# I2C3 register map
Vendor: Texas Instruments
Peripheral module from a debugger description file (folder omap4430).
Registers are 16-bit, access per field, reset 0x0 unless marked. A register's access mark holds for its fields unless they carry their own. Offsets are as the file gives them; lines under a group give offsets from that group; [hi:lo] are bit positions; {n}, {i} and the like mark numbered series; 'fields as' and 'values as' point back to an identical list; <NAME> marks a mode.

## I2C3
0x00 I2C_REVNB_LO 32-bit ro reset not defined — IP Revision Identifier (X.Y.R) Used by software to track features, bugs, and compatibility
  [31:0] REVISION — IP Revision
0x04 I2C_REVNB_HI 32-bit ro reset not defined — IP Revision Identifier (X.Y.R) Used by software to track features, bugs, and compatibility
  [31:0] REVISION — IP Revision
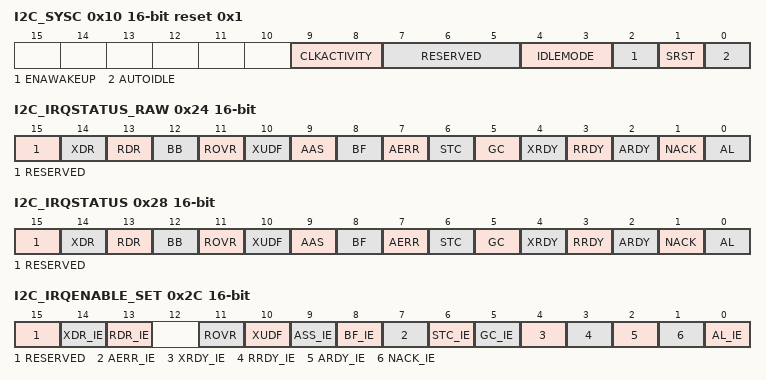
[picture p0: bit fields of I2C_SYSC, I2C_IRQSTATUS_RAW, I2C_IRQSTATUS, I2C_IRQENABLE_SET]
0x10 I2C_SYSC reset 0x1 — System Configuration register
  [9:8] CLKACTIVITY rw — Clock Activity selection bits
    0=Both clocks can be cut off; 1=Only OCP clock must be kept active; system clock can be cut off; 3=Both clocks must be kept active; 2=Only system clock must be kept active; OCP clock can be cut off
  [7:5] RESERVED ro — Reads return 0.
  [4:3] IDLEMODE rw — Idle Mode selection bits
    0=Force Idle mode; 1=No Idle mode; 3=smartidle_wakeup; 2=Smart Idle mode
  [2] ENAWAKEUP rw — Enable Wakeup control bit
    0=Wakeup mechanism is disabled; 1=Wakeup mechanism is enabled
  [1] SRST rw — SoftReset bit
    0=Normal mode; 1=The module is reset
  [0] AUTOIDLE rw — Autoidle bit
    0=Auto Idle mechanism is disabled; 1=Auto Idle mechanism is enabled
0x24 I2C_IRQSTATUS_RAW — Per-event raw interrupt status vector
  [15] RESERVED rw — Write 0s for future compatibility. Read returns 0.
  [14] XDR rw — Transmit draining IRQ status.
    0=Transmit draining inactive; 1=Transmit draining enabled
  [13] RDR rw — Receive draining IRQ status.
    0=Receive draining inactive; 1=Receive draining enabled
  [12] BB ro — Bus busy status.Writing into this bit has no effect.
    1=BB_1_r (Bus is occupied.); 0=BB_0_r (Bus is free.)
  [11] ROVR rw — Receive overrun status.Writing into this bit has no effect.
    1=ROVR_1_r (Receiver overrun.); 0=ROVR_0_r (Normal operation.)
  [10] XUDF rw — Transmit underflow status.Writing into this bit has no effect.
    1=XUDF_1_r (Transmit underflow.); 0=XUDF_0_r (Normal operation.)
  [9] AAS rw — Address recognized as slave IRQ status.
    0=No action; 1=Address recognized
  [8] BF rw — Bus Free IRQ status.
    0=No action; 1=Bus Free
  [7] AERR rw — Access Error IRQ status.
    0=No action; 1=Access Error
  [6] STC rw — Start Condition IRQ status.
    0=No action; 1=Start Condition detected
  [5] GC rw — General call IRQ status. Set to 1 by core when General call address detected and interrupt signaled to MPUSS.
    0=No general call detected; 1=General call address detected
  [4] XRDY rw — Transmit data ready IRQ status. Set to 1 by core when transmitter and when new data is requested. When set to 1 by core, an interrupt is signaled to MPUSS.
    0=Transmision ongoing; 1=Transmit data ready
  [3] RRDY rw — Receive data ready IRQ status. Set to 1 by core when receiver mode, a new data is able to be read. When set to 1 by core, an interrupt is signaled to MPUSS.
    0=No data available; 1=Receive data available
  [2] ARDY rw — Register access ready IRQ status. When set to 1 it indicates that previous access has been performed and registers are ready to be accessed again. An interrupt is signaled to MPUSS.
    0=Module busy; 1=Access ready
  [1] NACK rw — No acknowledgement IRQ status. Bit is set when No Acknowledge has been received, an interrupt is signaled to MPUSS.
    0=Normal operation; 1=Not Acknowledge detected
  [0] AL rw — Arbitration lost IRQ status. This bit is automatically set by the hardware when it loses the Arbitration in master transmit mode, an interrupt is signaled to MPUSS. During reads, it always returns 0.
    0=Normal operation; 1=Arbitration lost detected
0x28 I2C_IRQSTATUS access not given — Per-event enabled interrupt status vector
  [15] RESERVED rw — Write 0s for future compatibility. Read returns 0.
  [14] XDR — Transmit draining IRQ enabled status. (access RW W1toClr)
    0=Transmit draining inactive; 1=Transmit draining enabled
  [13] RDR — Receive draining IRQ enabled status. (access RW W1toClr)
    0=Receive draining inactive; 1=Receive draining enabled
  [12] BB ro — Bus busy enabled status.Writing into this bit has no effect.
    1=BB_1_r (Bus is occupied.); 0=BB_0_r (Bus is free.)
  [11] ROVR — Receive overrun enabled status.Writing into this bit has no effect. (access RW W1toClr)
    values as I2C_IRQSTATUS_RAW.ROVR
  [10] XUDF — Transmit underflow enabled status.Writing into this bit has no effect. (access RW W1toClr)
    values as I2C_IRQSTATUS_RAW.XUDF
  [9] AAS — Address recognized as slave IRQ enabled status. (access RW W1toClr)
    0=No action; 1=Address recognized
  [8] BF — Bus Free IRQ enabled status. (access RW W1toClr)
    0=No action; 1=Bus Free
  [7] AERR — Access Error IRQ enabled status. (access RW W1toClr)
    0=No action; 1=Access Error
  [6] STC — Start Condition IRQ enabled status. (access RW W1toClr)
    0=No action; 1=Start Condition detected
  [5] GC — General call IRQ enabled status. Set to 1 by core when General call address detected and interrupt signaled to MPUSS. Write 1 to clear. (access RW W1toClr)
    0=No general call detected; 1=General call address detected
  [4] XRDY — Transmit data ready IRQ enabled status. Set to 1 by core when transmitter and when new data is requested. When set to 1 by core, an interrupt is signaled to MPUSS. Write 1 to clear. (access RW W1toClr)
    0=Transmision ongoing; 1=Transmit data ready
  [3] RRDY — Receive data ready IRQ enabled status. Set to 1 by core when receiver mode, a new data is able to be read. When set to 1 by core, an interrupt is signaled to MPUSS. Write 1 to clear. (access RW W1toClr)
    0=No data available; 1=Receive data available
  [2] ARDY — Register access ready IRQ enabled status. When set to 1 it indicates that previous access has been performed and registers are ready to be accessed again. An interrupt is signaled to MPUSS. Write 1 to clear. (access RW W1toClr)
    0=Module busy; 1=Access ready
  [1] NACK — No acknowledgement IRQ enabled status. Bit is set when No Acknowledge has been received, an interrupt is signaled to MPUSS. Write 1 to clear this bit. (access RW W1toClr)
    0=Normal operation; 1=Not Acknowledge detected
  [0] AL — Arbitration lost IRQ enabled status. This bit is automatically set by the hardware when it loses the Arbitration in master transmit mode, an interrupt is signaled to MPUSS. During reads, it always returns 0. (access RW W1toClr)
    0=Normal operation; 1=Arbitration lost detected
0x2C I2C_IRQENABLE_SET — Per-event interrupt enable bit vector.
  [15] RESERVED rw — Write 0s for future compatibility. Read returns 0.
  [14] XDR_IE rw — Transmit Draining interrupt enable set. Mask or unmask the interrupt signaled by bit inI2C_STAT[XDR].
    0=Transmit Draining interrupt disabled; 1=Transmit Draining interrupt enabled
  [13] RDR_IE rw — Receive Draining interrupt enable set. Mask or unmask the interrupt signaled by bit inI2C_STAT[RDR].
    0=Receive Draining interrupt disabled; 1=Receive Draining interrupt enabled
  [11] ROVR rw — Receive overrun enable set.
    0=Receive overrun interrupt disabled; 1=Receive Draining interrupt enabled
  [10] XUDF rw — Transmit underflow enable set.
    0=Transmit underflow interrupt disabled; 1=Transmit underflow interrupt enabled
  [9] ASS_IE rw — Addressed as Slave interrupt enable set. Mask or unmask the interrupt signaled by bit inI2C_STAT[AAS].
    0=Addressed as Slave interrupt disabled; 1=Addressed as Slave interrupt enabled
  [8] BF_IE rw — Bus Free interrupt enable set. Mask or unmask the interrupt signaled by bit inI2C_STAT[BF].
    0=Bus Free interrupt disabled; 1=Bus Free interrupt enabled
  [7] AERR_IE rw — Access Error interrupt enable set. Mask or unmask the interrupt signaled by bit inI2C_STAT[AERR].
    0=Access Error interrupt disabled; 1=Access Error interrupt enabled
  [6] STC_IE rw — Start Condition interrupt enable set. Mask or unmask the interrupt signaled by bit inI2C_STAT[STC].
    0=Start Condition interrupt disabled; 1=Start Condition interrupt enabled
  [5] GC_IE rw — General call Interrupt enable set. Mask or unmask the interrupt signaled by bit inI2C_STAT[GC]
    0=General call interrupt disabled; 1=General call interrupt enabled
  [4] XRDY_IE rw — Transmit data ready interrupt enable set. Mask or unmask the interrupt signaled by bit inI2C_STAT[XRDY]
    0=Transmit data ready interrupt disabled; 1=Transmit data ready interrupt enabled
  [3] RRDY_IE rw — Receive data ready interrupt enable set. Mask or unmask the interrupt signaled by bit inI2C_STAT[RRDY]
    0=Receive data ready interrupt disabled; 1=Receive data ready interrupt enabled
  [2] ARDY_IE rw — Register access ready interrupt enable set. Mask or unmask the interrupt signaled by bit inI2C_STAT[ARDY]
    0=Register access ready interrupt disabled; 1=Register access ready interrupt enabled
  [1] NACK_IE rw — No acknowledgement interrupt enable set. Mask or unmask the interrupt signaled by bit inI2C_STAT[NACK]
    0=Not Acknowledge interrupt disabled; 1=Not Acknowledge interrupt enabled
  [0] AL_IE rw — Arbitration lost interrupt enable set. Mask or unmask the interrupt signaled by bit inI2C_STAT[AL]
    0=Arbitration lost interrupt disabled; 1=Arbitration lost interrupt enabled
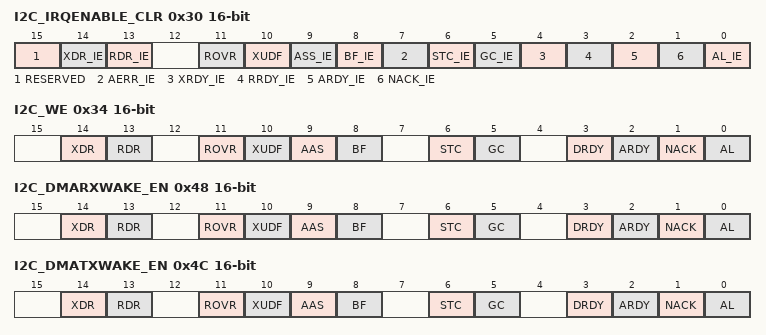
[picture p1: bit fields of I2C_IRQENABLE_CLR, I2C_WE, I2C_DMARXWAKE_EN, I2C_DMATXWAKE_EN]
0x30 I2C_IRQENABLE_CLR — Per-event interrupt clear bit vector.
  [15] RESERVED rw — Write 0s for future compatibility. Read returns 0.
  [14] XDR_IE rw — Transmit Draining interrupt enable clear. Mask or unmask the interrupt signaled by bit inI2C_STAT[XDR].
    values as I2C_IRQENABLE_SET.XDR_IE
  [13] RDR_IE rw — Receive Draining interrupt enable clear. Mask or unmask the interrupt signaled by bit inI2C_STAT[RDR].
    values as I2C_IRQENABLE_SET.RDR_IE
  [11] ROVR rw — Receive overrun enable clear.
    values as I2C_IRQENABLE_SET.ROVR
  [10] XUDF rw — Transmit underflow enable clear.
    values as I2C_IRQENABLE_SET.XUDF
  [9] ASS_IE rw — Addressed as Slave interrupt enable clear. Mask or unmask the interrupt signaled by bit inI2C_STAT[AAS].
    values as I2C_IRQENABLE_SET.ASS_IE
  [8] BF_IE rw — Bus Free interrupt enable clear. Mask or unmask the interrupt signaled by bit inI2C_STAT[BF].
    0=Bus Free interrupt disabled; 1=Bus Free interrupt enabled
  [7] AERR_IE rw — Access Error interrupt enable clear. Mask or unmask the interrupt signaled by bit inI2C_STAT[AERR].
    values as I2C_IRQENABLE_SET.AERR_IE
  [6] STC_IE rw — Start Condition interrupt enable clear. Mask or unmask the interrupt signaled by bit inI2C_STAT[STC].
    values as I2C_IRQENABLE_SET.STC_IE
  [5] GC_IE rw — General call Interrupt enable clear. Mask or unmask the interrupt signaled by bit inI2C_STAT[GC]
    values as I2C_IRQENABLE_SET.GC_IE
  [4] XRDY_IE rw — Transmit data ready interrupt enable clear. Mask or unmask the interrupt signaled by bit inI2C_STAT[XRDY]
    values as I2C_IRQENABLE_SET.XRDY_IE
  [3] RRDY_IE rw — Receive data ready interrupt enable clear. Mask or unmask the interrupt signaled by bit inI2C_STAT[RRDY]
    values as I2C_IRQENABLE_SET.RRDY_IE
  [2] ARDY_IE rw — Register access ready interrupt enable clear. Mask or unmask the interrupt signaled by bit inI2C_STAT[ARDY]
    values as I2C_IRQENABLE_SET.ARDY_IE
  [1] NACK_IE rw — No acknowledgement interrupt enable clear. Mask or unmask the interrupt signaled by bit inI2C_STAT[NACK]
    values as I2C_IRQENABLE_SET.NACK_IE
  [0] AL_IE rw — Arbitration lost interrupt enable clear. Mask or unmask the interrupt signaled by bit inI2C_STAT[AL]
    values as I2C_IRQENABLE_SET.AL_IE
0x34 I2C_WE — I2C wakeup enable vector.
  [14] XDR rw — Transmit Draining wakeup set.
    0=Transmit draining wakeup disabled; 1=Transmit draining wakeup enabled
  [13] RDR rw — Receive Draining wakeup set.
    0=Receive draining wakeup disabled; 1=Receive draining wakeup enabled
  [11] ROVR rw — Receive overrun wakeup set.
    0=Receive overrun wakeup disabled; 1=Receive overrun wakeup enabled
  [10] XUDF rw — Transmit underflow wakeup set.
    0=Transmit underflow wakeup disabled; 1=Transmit underflow wakeup enabled
  [9] AAS rw — Address as slave IRQ wakeup set.
    0=Addressed as slave wakeup disabled; 1=Addressed as slave wakeup enabled
  [8] BF rw — Bus Free IRQ wakeup set.
    0=Bus Free wakeup disabled; 1=Bus Free wakeup enabled
  [6] STC rw — Start Condition IRQ wakeup set.
    0=Start condition wakeup disabled; 1=Start condition wakeup enabled
  [5] GC rw — General call IRQ wakeup set.
    0=General call wakeup disabled; 1=General call wakeup enabled
  [3] DRDY rw — Receive/Transmit data ready IRQ wakeup set.
    0=Transmit/receive data ready wakeup disabled; 1=Transmit/receive data ready wakeup enabled
  [2] ARDY rw — Register access ready IRQ wakeup set.
    0=Register access ready wakeup disabled; 1=Register access ready wakeup enabled
  [1] NACK rw — No acknowledgment IRQ wakeup set.
    0=Not Acknowledge wakeup disabled; 1=Not Acknowledge wakeup enabled
  [0] AL rw — Arbitration lost IRQ wakeup set.
    0=Arbitration lost wakeup disabled; 1=Arbitration lost wakeup enabled
0x38 I2C_DMARXENABLE_SET — Per-event DMA RX enable set.
  [0] DMARX_ENABLE_SET rw — Receive DMA channel enable set.
0x3C I2C_DMATXENABLE_SET — Per-event DMA TX enable set.
  [0] DMATX_ENABLE_SET rw — Transmit DMA channel enable set.
0x40 I2C_DMARXENABLE_CLR — Per-event DMA RX enable clear.
  [0] DMARX_ENABLE_CLEAR rw — Receive DMA channel enable clear.
0x44 I2C_DMATXENABLE_CLR — Per-event DMA TX enable clear.
  [0] DMATX_ENABLE_CLEAR rw — Transmit DMA channel enable clear.
0x48 I2C_DMARXWAKE_EN — Per-event DMA RX wakeup enable.
  fields as I2C_WE
0x4C I2C_DMATXWAKE_EN — Per-event DMA TX wakeup enable.
  fields as I2C_WE
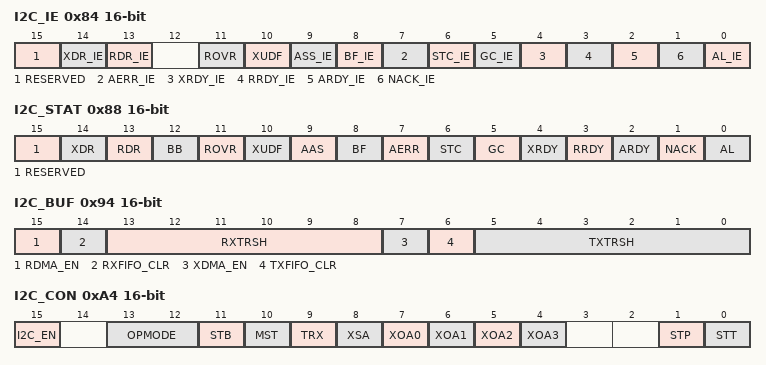
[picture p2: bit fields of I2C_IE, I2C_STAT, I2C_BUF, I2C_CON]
0x84 I2C_IE — I2C interrupt enable vector (legacy).
  [15] RESERVED rw — Write 0s for future compatibility. Read returns 0.
  [14] XDR_IE rw — Transmit Draining interrupt enable. Mask or unmask the interrupt signaled by bit inI2C_STAT[XDR].
    values as I2C_IRQENABLE_SET.XDR_IE
  [13] RDR_IE rw — Receive Draining interrupt enable. Mask or unmask the interrupt signaled by bit inI2C_STAT[RDR].
    values as I2C_IRQENABLE_SET.RDR_IE
  [11] ROVR rw — Receive overrun enable set.
    values as I2C_IRQENABLE_SET.ROVR
  [10] XUDF rw — Transmit underflow enable set.
    values as I2C_IRQENABLE_SET.XUDF
  [9] ASS_IE rw — Addressed as Slave interrupt enable. Mask or unmask the interrupt signaled by bit inI2C_STAT[AAS].
    values as I2C_IRQENABLE_SET.ASS_IE
  [8] BF_IE rw — Bus Free interrupt enable. Mask or unmask the interrupt signaled by bit inI2C_STAT[BF].
    0=Bus Free interrupt disabled; 1=Bus Free interrupt enabled
  [7] AERR_IE rw — Access Error interrupt enable. Mask or unmask the interrupt signaled by bit inI2C_STAT[AERR].
    values as I2C_IRQENABLE_SET.AERR_IE
  [6] STC_IE rw — Start Condition interrupt enable. Mask or unmask the interrupt signaled by bit inI2C_STAT[STC].
    values as I2C_IRQENABLE_SET.STC_IE
  [5] GC_IE rw — General call Interrupt enable. Mask or unmask the interrupt signaled by bit inI2C_STAT[GC]
    values as I2C_IRQENABLE_SET.GC_IE
  [4] XRDY_IE rw — Transmit data ready interrupt enable. Mask or unmask the interrupt signaled by bit inI2C_STAT[XRDY]
    values as I2C_IRQENABLE_SET.XRDY_IE
  [3] RRDY_IE rw — Receive data ready interrupt enable. Mask or unmask the interrupt signaled by bit inI2C_STAT[RRDY]
    values as I2C_IRQENABLE_SET.RRDY_IE
  [2] ARDY_IE rw — Register access ready interrupt enable. Mask or unmask the interrupt signaled by bit inI2C_STAT[ARDY]
    values as I2C_IRQENABLE_SET.ARDY_IE
  [1] NACK_IE rw — No acknowledgement interrupt enable. Mask or unmask the interrupt signaled by bit inI2C_STAT[NACK]
    values as I2C_IRQENABLE_SET.NACK_IE
  [0] AL_IE rw — Arbitration lost interrupt enable. Mask or unmask the interrupt signaled by bit inI2C_STAT[AL]
    values as I2C_IRQENABLE_SET.AL_IE
0x88 I2C_STAT access not given — I2C interrupt status vector (legacy).
  [15] RESERVED rw — Write 0s for future compatibility. Read returns 0.
  [14] XDR — Transmit draining IRQ status. (access RW W1toClr)
    0=Transmit draining inactive; 1=Transmit draining enabled
  [13] RDR — Receive draining IRQ status. (access RW W1toClr)
    0=Receive draining inactive; 1=Receive draining enabled
  [12] BB ro — Bus busy status.Writing into this bit has no effect.
    1=BB_1_r (Bus is occupied.); 0=BB_0_r (Bus is free.)
  [11] ROVR — Receive overrun status.Writing into this bit has no effect. (access RW W1toClr)
    values as I2C_IRQSTATUS_RAW.ROVR
  [10] XUDF — Transmit underflow status.Writing into this bit has no effect. (access RW W1toClr)
    values as I2C_IRQSTATUS_RAW.XUDF
  [9] AAS — Address recognized as slave IRQ status. (access RW W1toClr)
    0=No action; 1=Address recognized
  [8] BF — Bus Free IRQ status. (access RW W1toClr)
    0=No action; 1=Bus Free
  [7] AERR — Access Error IRQ status. (access RW W1toClr)
    0=No action; 1=Access Error
  [6] STC — Start Condition IRQ status. (access RW W1toClr)
    0=No action; 1=Start Condition detected
  [5] GC — General call IRQ status. Set to 1 by core when General call address detected and interrupt signaled to MPUSS. Write 1 to clear. (access RW W1toClr)
    0=No general call detected; 1=General call address detected
  [4] XRDY — Transmit data ready IRQ status. Set to 1 by core when transmitter and when new data is requested. When set to 1 by core, an interrupt is signaled to MPUSS. Write 1 to clear. (access RW W1toClr)
    0=Transmision ongoing; 1=Transmit data ready
  [3] RRDY — Receive data ready IRQ status. Set to 1 by core when receiver mode, a new data is able to be read. When set to 1 by core, an interrupt is signaled to MPUSS. Write 1 to clear. (access RW W1toClr)
    0=No data available; 1=Receive data available
  [2] ARDY — Register access ready IRQ status. When set to 1 it indicates that previous access has been performed and registers are ready to be accessed again. An interrupt is signaled to MPUSS. Write 1 to clear. (access RW W1toClr)
    0=Module busy; 1=Access ready
  [1] NACK — No acknowledgement IRQ status. Bit is set when No Acknowledge has been received, an interrupt is signaled to MPUSS. Write 1 to clear this bit. (access RW W1toClr)
    0=Normal operation; 1=Not Acknowledge detected
  [0] AL — Arbitration lost IRQ status. This bit is automatically set by the hardware when it loses the Arbitration in master transmit mode, an interrupt is signaled to MPUSS. During reads, it always returns 0. (access RW W1toClr)
    0=Normal operation; 1=Arbitration lost detected
0x90 I2C_SYSS reset 0x1 — System Status register
  [0] RDONE rw — Reset done bit
    1=RDONE_1_r (Reset completed); 0=RDONE_0_r (Internal module reset in ongoing)
0x94 I2C_BUF rw — Buffer Configuration register
  [15] RDMA_EN — Receive DMA channel enable
    0=Receive DMA channel disabled; 1=Receive DMA channel enabled
  [14] RXFIFO_CLR — Receive FIFO clear
    0=Normal mode; 1=Rx FIFO is reset
  [13:8] RXTRSH — Threshold value for FIFO buffer in RX mode
  [7] XDMA_EN — Transmit DMA channel enable
    0=Transmit DMA channel disabled; 1=Transmit DMA channel enabled
  [6] TXFIFO_CLR — Transmit FIFO clear
    0=Normal mode; 1=Tx FIFO is reset
  [5:0] TXTRSH — Threshold value for FIFO buffer in TX mode
0x98 I2C_CNT rw — Data counter register
  [15:0] DCOUNT — Data count Because the transfer length for DCOUNT = 0x0000 is 65536, the module does not allow the initiation of zero-data-byte transfers.
0x9C I2C_DATA (reset mask 0xFF00) — Data access register
  [7:0] DATA rw — Transmit/Receive data FIFO endpoint
0xA4 I2C_CON — I2C configuration register.
  [15] I2C_EN rw — I2C module enable.
    0=Controller in reset. FIFO are cleared and status bits are set to their default value; 1=Module enabled
  [13:12] OPMODE rw — Operation mode selection.
    0=I2C Fast/Standard mode; 1=I2C High Speed mode; 2=SCCB mode
  [11] STB rw — Start byte mode (master mode only).
    0=Normal mode; 1=Start byte mode
  [10] MST rw — Master/slave mode.
    0=Slave mode; 1=Master mode
  [9] TRX rw — Transmitter/Receiver mode (master mode only).
    0=Receiver mode; 1=Transmitter mode
  [8] XSA rw — Expand Slave address.
    0=7-bit address mode; 1=10-bit address mode
  [7-n] XOA{n} rw (n=0..3) — Expand Own address {n}.
    0=7-bit address mode; 1=10-bit address mode
  [1] STP rw — Stop condition (master mode only).
    0=No action or stop condition detected; 1=Stop condition queried
  [0] STT rw — Start condition (master mode only).
    0=No action or start condition detected; 1=Start condition queried
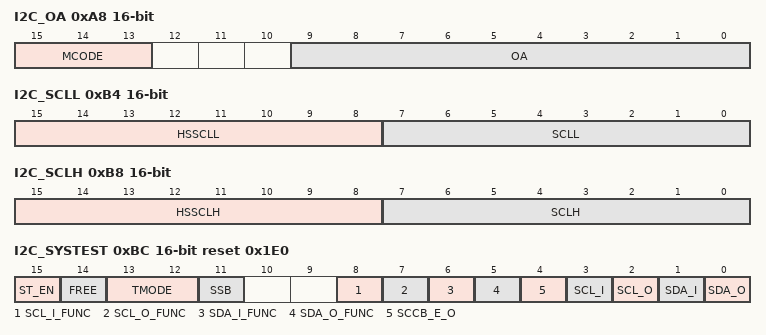
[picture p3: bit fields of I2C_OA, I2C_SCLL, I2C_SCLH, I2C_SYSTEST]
0xA8 I2C_OA — Own address register
  [15:13] MCODE rw — Master Code
  [9:0] OA rw — Own address
0xAC I2C_SA reset 0x3FF — Slave address register
  [9:0] SA rw — Slave address
0xB0 I2C_PSC — I2C Clock Prescaler Register
  [7:0] PSC rw — Fast/Standard mode prescale sampling clock divider value 0x0: Divide by 1 0x1: Divide by 2 .............................. 0xFF: Divide by 256
0xB4 I2C_SCLL rw — I2C SCL Low Time Register.
  [15:8] HSSCLL — High Speed mode SCL low time
  [7:0] SCLL — Fast/Standard mode SCL low time.
0xB8 I2C_SCLH rw — I2C SCL High Time Register.
  [15:8] HSSCLH — High Speed mode SCL high time
  [7:0] SCLH — Fast/Standard mode SCL high time.
0xBC I2C_SYSTEST reset 0x1E0 — I2C System Test Register.
  [15] ST_EN rw — System test enable.
    0=Normal mode. All others bits in register are read only; 1=System test enabled. Permit other system test registers bits to be set
  [14] FREE rw — Free running mode (on breakpoint)
    0=Stop mode (on breakpoint condition). If Master mode, it stops after completion of the ongoing bit transfer. In slave mode, it stops during the phase transfer when 1 byte is completely transmitted/received.; 1=Free running mode
  [13:12] TMODE rw — Test mode select.
    0=Functional mode (default); 3=Loop back mode select + SDA/SCL IO mode select; 2=Test of SCL counters (SCLL, SCLH, PSC). SCL provides a permanent clock with master mode.
  [11] SSB rw — Set status bits from 0 to 14.
    0=No action; 1=Set interrupt status bits to 1
  [8] SCL_I_FUNC ro — SCL line input value (functional mode).
    1=SCL_I_FUNC_1_r (Read 1 from SCL line); 0=SCL_I_FUNC_0_r (Read 0 from SCL line)
  [7] SCL_O_FUNC ro — SCL line output value (functional mode).
    1=SCL_O_FUNC_1_r (Driven 1 on SCL line); 0=SCL_O_FUNC_0_r (Driven 0 on SCL line)
  [6] SDA_I_FUNC ro — SDA line input value (functional mode).
    1=SDA_I_FUNC_1_r (Read 1 from SDA line); 0=SDA_I_FUNC_0_r (Read 0 from SDA line)
  [5] SDA_O_FUNC ro — SDA line output value (functional mode).
    1=SDA_O_FUNC_1_r (Driven 1 to SDA line); 0=SDA_O_FUNC_0_r (Driven 0 to SDA line)
  [4] SCCB_E_O rw — SCCB_E line sense output value.
    0=Write 0 to SCCBE line; 1=Write 1 to SCCBE line
  [3] SCL_I ro — SCL line sense input value
    1=SCL_I_1_r (Read 1 from SCL line); 0=SCL_I_0_r (Read 0 from SCL line)
  [2] SCL_O rw — SCL line drive output value.
    0=Write 0 to SCL line; 1=Write 1 to SCL line
  [1] SDA_I ro — SDA line sense input value.
    1=SDA_I_1_r (Read 1 from SDA line); 0=SDA_I_0_r (Read 0 from SDA line)
  [0] SDA_O rw — SDA line drive output value.
    0=Write 0 to SDA line; 1=Write 1 to SDA line
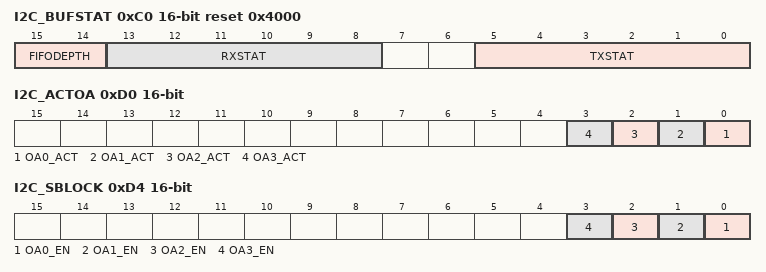
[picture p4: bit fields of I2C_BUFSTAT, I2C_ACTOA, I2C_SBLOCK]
0xC0 I2C_BUFSTAT ro reset 0x4000 — I2C Buffer Status Register.
  [15:14] FIFODEPTH — Internal FIFO buffers depth.
  [13:8] RXSTAT — RX Buffer Status
  [5:0] TXSTAT — TX Buffer Status.
{0xC0+4i} I2C_OA{i} (i=1..3) — I2C Own Address {i} Register
  [9:0] OA{i} rw — Own address {i}
0xD0 I2C_ACTOA ro — I2C Active Own Address Register.
  [n] OA{n}_ACT (n=0..3) — Own Address {n} active.
    1=OA{n}_ACT_1_r (Own Address active.); 0=OA{n}_ACT_0_r (Own Address inactive.)
0xD4 I2C_SBLOCK — I2C Clock Blocking Enable Register.
  [all] fields
    0=I2C Clock Released; 1=I2C Clock Blocked
  [n] OA{n}_EN rw (n=0..3) — Enable I2C Clock Blocking for Own Address {n}.
